VERSION ""

NS_ :

BS_:

BU_: Vector__XXX

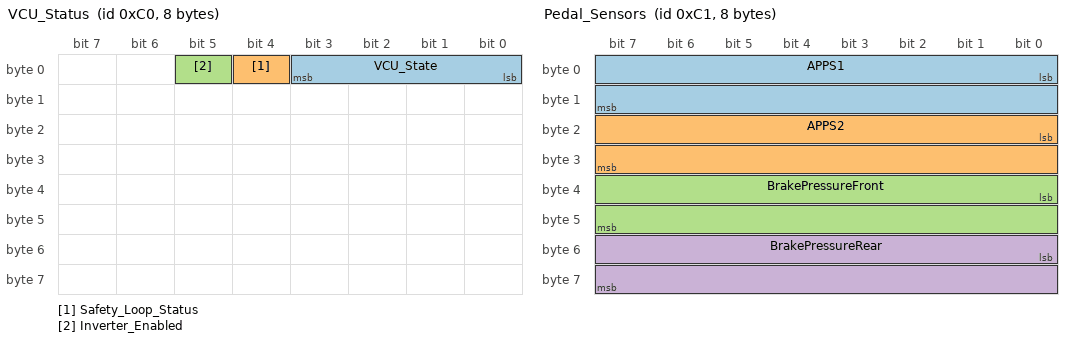
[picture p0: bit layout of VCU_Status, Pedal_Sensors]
BO_ 192 VCU_Status: 8 Vector__XXX
 SG_ VCU_State : 0|4@1+ (1,0) [0|15] "" Vector__XXX
 SG_ Safety_Loop_Status : 4|1@1+ (1,0) [0|1] "" Vector__XXX
 SG_ Inverter_Enabled : 5|1@1+ (1,0) [0|1] "" Vector__XXX

BO_ 193 Pedal_Sensors: 8 Vector__XXX
 SG_ APPS1 : 0|16@1+ (0.1,0) [0|100] "%" Vector__XXX
 SG_ APPS2 : 16|16@1+ (0.1,0) [0|100] "%" Vector__XXX
 SG_ BrakePressureFront : 32|16@1+ (0.1,0) [0|200] "bar" Vector__XXX
 SG_ BrakePressureRear : 48|16@1+ (0.1,0) [0|200] "bar" Vector__XXX

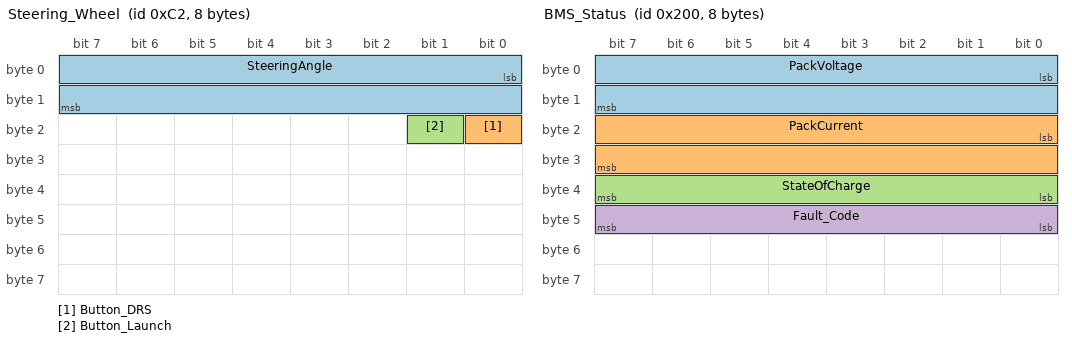
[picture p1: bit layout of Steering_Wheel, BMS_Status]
BO_ 194 Steering_Wheel: 8 Vector__XXX
 SG_ SteeringAngle : 0|16@1- (0.1,0) [-180|180] "deg" Vector__XXX
 SG_ Button_DRS : 16|1@1+ (1,0) [0|1] "" Vector__XXX
 SG_ Button_Launch : 17|1@1+ (1,0) [0|1] "" Vector__XXX

BO_ 512 BMS_Status: 8 Vector__XXX
 SG_ PackVoltage : 0|16@1+ (0.1,0) [0|600] "V" Vector__XXX
 SG_ PackCurrent : 16|16@1- (0.1,0) [-300|300] "A" Vector__XXX
 SG_ StateOfCharge : 32|8@1+ (0.5,0) [0|100] "%" Vector__XXX
 SG_ Fault_Code : 40|8@1+ (1,0) [0|255] "" Vector__XXX

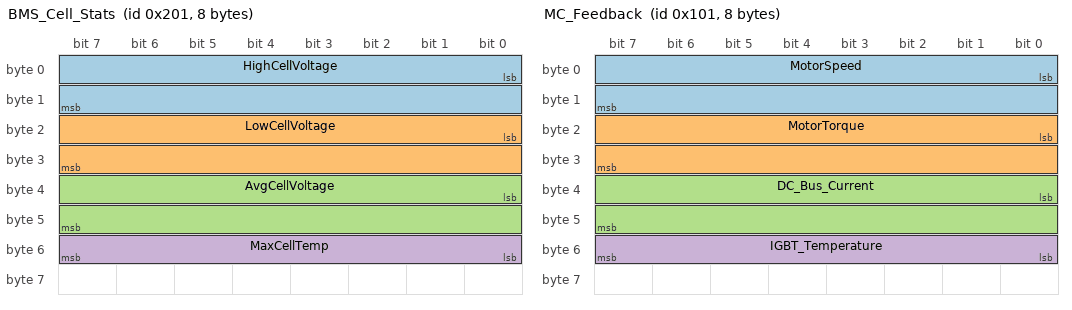
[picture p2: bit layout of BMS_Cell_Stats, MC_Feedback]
BO_ 513 BMS_Cell_Stats: 8 Vector__XXX
 SG_ HighCellVoltage : 0|16@1+ (0.001,0) [0|5] "V" Vector__XXX
 SG_ LowCellVoltage : 16|16@1+ (0.001,0) [0|5] "V" Vector__XXX
 SG_ AvgCellVoltage : 32|16@1+ (0.001,0) [0|5] "V" Vector__XXX
 SG_ MaxCellTemp : 48|8@1+ (1,-40) [-40|150] "C" Vector__XXX

BO_ 256 MC_Command: 8 Vector__XXX
 SG_ TorqueRequest : 0|16@1- (0.1,0) [-300|300] "Nm" Vector__XXX
 SG_ SpeedLimit : 16|16@1+ (1,0) [0|10000] "rpm" Vector__XXX

BO_ 257 MC_Feedback: 8 Vector__XXX
 SG_ MotorSpeed : 0|16@1- (1,0) [-10000|10000] "rpm" Vector__XXX
 SG_ MotorTorque : 16|16@1- (0.1,0) [-300|300] "Nm" Vector__XXX
 SG_ DC_Bus_Current : 32|16@1- (0.1,0) [-300|300] "A" Vector__XXX
 SG_ IGBT_Temperature : 48|8@1+ (1,-40) [-40|150] "C" Vector__XXX

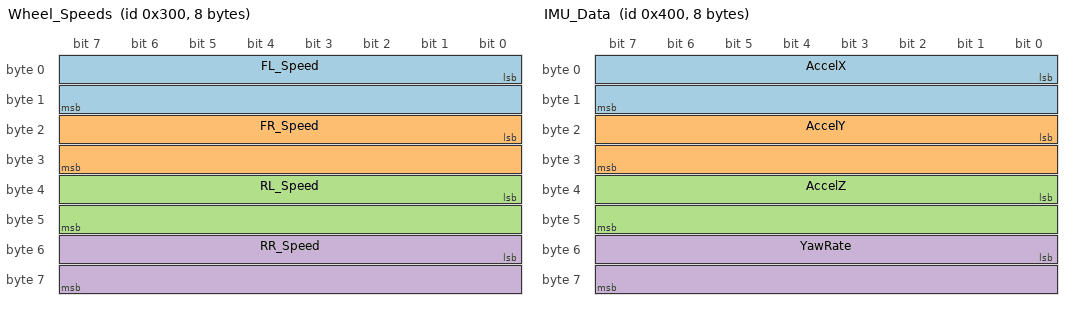
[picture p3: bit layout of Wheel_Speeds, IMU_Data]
BO_ 768 Wheel_Speeds: 8 Vector__XXX
 SG_ FL_Speed : 0|16@1+ (1,0) [0|3000] "rpm" Vector__XXX
 SG_ FR_Speed : 16|16@1+ (1,0) [0|3000] "rpm" Vector__XXX
 SG_ RL_Speed : 32|16@1+ (1,0) [0|3000] "rpm" Vector__XXX
 SG_ RR_Speed : 48|16@1+ (1,0) [0|3000] "rpm" Vector__XXX

BO_ 1024 IMU_Data: 8 Vector__XXX
 SG_ AccelX : 0|16@1- (0.001,0) [-4|4] "g" Vector__XXX
 SG_ AccelY : 16|16@1- (0.001,0) [-4|4] "g" Vector__XXX
 SG_ AccelZ : 32|16@1- (0.001,0) [-4|4] "g" Vector__XXX
 SG_ YawRate : 48|16@1- (0.1,0) [-200|200] "deg/s" Vector__XXX

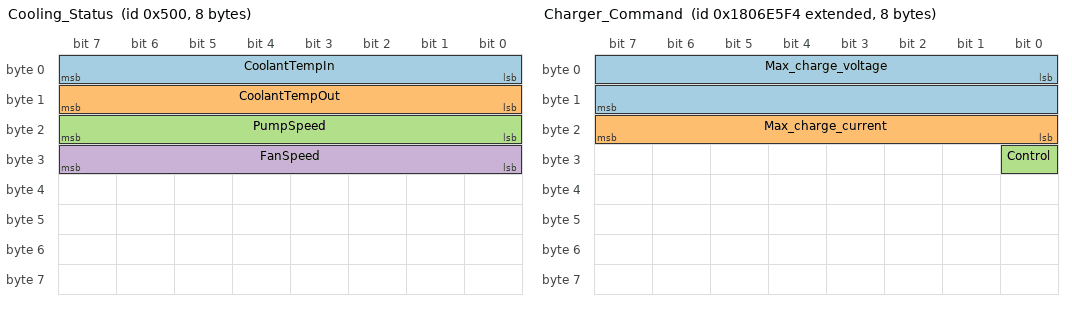
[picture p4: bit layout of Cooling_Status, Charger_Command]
BO_ 1280 Cooling_Status: 8 Vector__XXX
 SG_ CoolantTempIn : 0|8@1+ (1,-40) [-40|150] "C" Vector__XXX
 SG_ CoolantTempOut : 8|8@1+ (1,-40) [-40|150] "C" Vector__XXX
 SG_ PumpSpeed : 16|8@1+ (1,0) [0|100] "%" Vector__XXX
 SG_ FanSpeed : 24|8@1+ (1,0) [0|100] "%" Vector__XXX

BO_ 1999 Heartbeat: 8 Vector__XXX
 SG_ UTCTime : 0|64@1+ (1,0) [0|0] "YYYYMMDDHHMMSS" Vector__XXX

CM_ BO_ 192 "Vehicle Control Unit Status";
CM_ BO_ 193 "Pedal Box Sensor Data";
CM_ BO_ 194 "Steering Wheel Inputs";
CM_ BO_ 512 "Battery Management System Main Status";
CM_ BO_ 513 "Battery Management System Cell Statistics";
CM_ BO_ 256 "Motor Controller Command (from VCU)";
CM_ BO_ 257 "Motor Controller Feedback";
CM_ BO_ 768 "Wheel Speed Sensors";
CM_ BO_ 1024 "IMU 6-DOF Data";
CM_ BO_ 1280 "Cooling System Status";
CM_ BO_ 1999 "Pipeline Heartbeat";

BO_ 2550588916 Charger_Command: 8 Vector__XXX
 SG_ Max_charge_voltage : 0|16@1+ (0.1,0) [0|655.3] "V" Vector__XXX
 SG_ Max_charge_current : 16|8@1+ (0.1,0) [0|25.5] "A" Vector__XXX
 SG_ Control : 24|1@1+ (1,0) [0|1] "" Vector__XXX

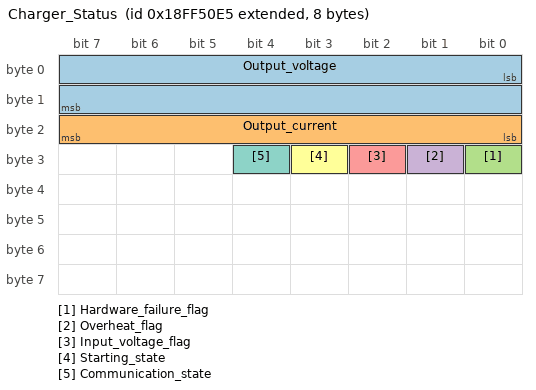
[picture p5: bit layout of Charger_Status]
BO_ 2566869221 Charger_Status: 8 Vector__XXX
 SG_ Output_voltage : 0|16@1+ (0.1,0) [0|655.3] "V" Vector__XXX
 SG_ Output_current : 16|8@1+ (0.1,0) [0|25.5] "A" Vector__XXX
 SG_ Hardware_failure_flag : 24|1@1+ (1,0) [0|1] "" Vector__XXX
 SG_ Overheat_flag : 25|1@1+ (1,0) [0|1] "" Vector__XXX
 SG_ Input_voltage_flag : 26|1@1+ (1,0) [0|1] "" Vector__XXX
 SG_ Starting_state : 27|1@1+ (1,0) [0|1] "" Vector__XXX
 SG_ Communication_state : 28|1@1+ (1,0) [0|1] "" Vector__XXX

CM_ BO_ 2550588916 "Charger command message (J1939 extended 29-bit frame)";
CM_ SG_ 2550588916 Max_charge_voltage "Max allowable charging terminal voltage";
CM_ SG_ 2550588916 Max_charge_current "Max allowable charging current";
CM_ SG_ 2550588916 Control "Toggle charging. 0 = start charging, 1 = stop charging";
CM_ BO_ 2566869221 "Charger status message (J1939 extended 29-bit frame)";
CM_ SG_ 2566869221 Output_voltage "Charger output voltage";
CM_ SG_ 2566869221 Output_current "Charger output current";
CM_ SG_ 2566869221 Hardware_failure_flag "0 = good, 1 = hardware failure";
CM_ SG_ 2566869221 Overheat_flag "0 = good, 1 = charger overheated and stopped charging";
CM_ SG_ 2566869221 Input_voltage_flag "0 = input voltage OK, 1 = input voltage wrong and charger halted";
CM_ SG_ 2566869221 Starting_state "0 = charger detects battery voltage and starts, 1 = stays off (anti-reverse-polarity)";
CM_ SG_ 2566869221 Communication_state "0 = communication OK, 1 = communication receive timeout";
